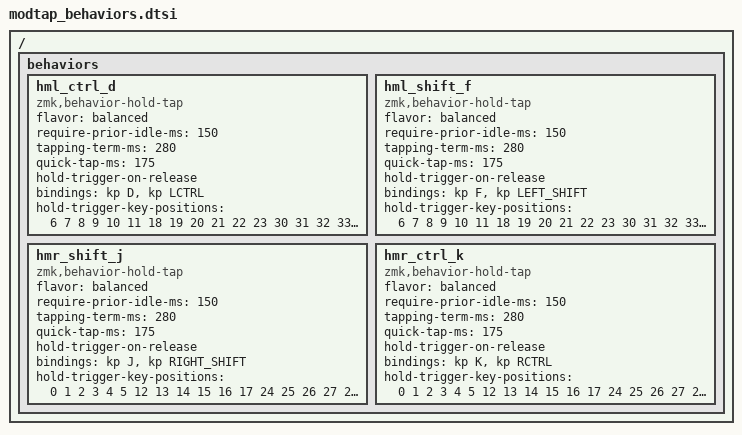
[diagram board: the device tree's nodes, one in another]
/ {
    behaviors {
        // Home row mod kiri: D sebagai Ctrl
        hml_ctrl_d: hml_ctrl_d {
            compatible = "zmk,behavior-hold-tap";
            #binding-cells = <2>;
            flavor = "balanced";
            require-prior-idle-ms = <150>;
            tapping-term-ms = <280>;
            quick-tap-ms = <175>;
            hold-trigger-on-release;
            bindings = <&kp D &kp LCTRL>;
            hold-trigger-key-positions = <
                6  7  8  9 10 11
               18 19 20 21 22 23
               30 31 32 33 34 35
               39 40 41
            >;
        };

        // Home row mod kiri: F sebagai Left Shift
        hml_shift_f: hml_shift_f {
            compatible = "zmk,behavior-hold-tap";
            #binding-cells = <2>;
            flavor = "balanced";
            require-prior-idle-ms = <150>;
            tapping-term-ms = <280>;
            quick-tap-ms = <175>;
            hold-trigger-on-release;
            bindings = <&kp F &kp LEFT_SHIFT>;
            hold-trigger-key-positions = <
                6  7  8  9 10 11
               18 19 20 21 22 23
               30 31 32 33 34 35
               39 40 41
            >;
        };

        // Home row mod kanan: J sebagai Right Shift
        hmr_shift_j: hmr_shift_j {
            compatible = "zmk,behavior-hold-tap";
            #binding-cells = <2>;
            flavor = "balanced";
            require-prior-idle-ms = <150>;
            tapping-term-ms = <280>;
            quick-tap-ms = <175>;
            hold-trigger-on-release;
            bindings = <&kp J &kp RIGHT_SHIFT>;
            hold-trigger-key-positions = <
                0  1  2  3  4  5
               12 13 14 15 16 17
               24 25 26 27 28 29
               36 37 38
            >;
        };

        // Home row mod kanan: K sebagai Right Ctrl
        hmr_ctrl_k: hmr_ctrl_k {
            compatible = "zmk,behavior-hold-tap";
            #binding-cells = <2>;
            flavor = "balanced";
            require-prior-idle-ms = <150>;
            tapping-term-ms = <280>;
            quick-tap-ms = <175>;
            hold-trigger-on-release;
            bindings = <&kp K &kp RCTRL>;
            hold-trigger-key-positions = <
                0  1  2  3  4  5
               12 13 14 15 16 17
               24 25 26 27 28 29
               36 37 38
            >;
        };
    };
};
